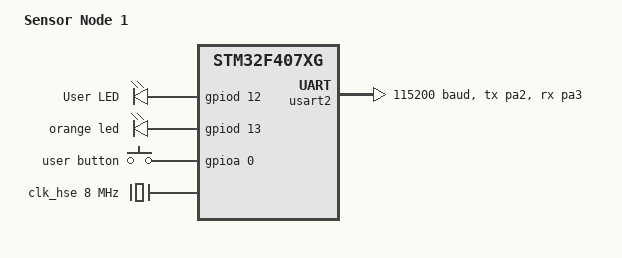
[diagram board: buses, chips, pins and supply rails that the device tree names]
/*
 * Copyright (c) 2017 Linaro Limited
 *
 * SPDX-License-Identifier: Apache-2.0
 */

/dts-v1/;
#include <st/f4/stm32f407Xg.dtsi>
#include <st/f4/stm32f407v(e-g)tx-pinctrl.dtsi>

/ {
	model = "Sensor Node 1";
	compatible = "st,sensor-node1";

	chosen {
		zephyr,console = &usart2;
		zephyr,shell-uart = &usart2;
		zephyr,sram = &sram0;
		zephyr,flash = &flash0;
	};

	/* Onboard LEDs - PD12/PD13 */
	leds {
		compatible = "gpio-leds";

		green_led: led_0 {
			gpios = <&gpiod 12 GPIO_ACTIVE_HIGH>;
			label = "User LED";
		};
		orange_led: led_1 {
			gpios = <&gpiod 13 GPIO_ACTIVE_HIGH>;
			label = "orange led";
		};
	};

	/* User button (B1) - PA0 */
	user_button {
		compatible = "gpio-keys";
		user_button1: button_1 {
			gpios = <&gpioa 0 GPIO_ACTIVE_HIGH>;
			label = "user button";
		};
	};

	aliases {
		led1 = &green_led;
		led2 = &orange_led;
		button1  = &user_button1;
	};
};

&clk_hse {
	clock-frequency = <DT_FREQ_M(8)>;
	status = "okay";
};

&pll {
	div-m = <8>;
	mul-n = <336>;
	div-p = <2>;
	div-q = <7>;
	clocks = <&clk_hse>;
	status = "okay";
};

&rcc {
	clocks = <&pll>;
	clock-frequency = <DT_FREQ_M(168)>;
	ahb-prescaler = <1>;
	apb1-prescaler = <4>;
	apb2-prescaler = <2>;
};

&usart2 {
	pinctrl-0 = <&usart2_tx_pa2 &usart2_rx_pa3>;
	pinctrl-names = "default";
	current-speed = <115200>;
	status = "okay";
};
